# CM0+ register map
CPU: CM0+ r0p0, selectable endian, MPU, no FPU, 2 interrupt priority bits
Registers are 32-bit, read-write, reset 0x0 unless marked. A register's access mark holds for its fields unless they carry their own. Offsets are from the block's base; [hi:lo] are bit positions.

## SCB — System Control Block
Base 0xE000ED00
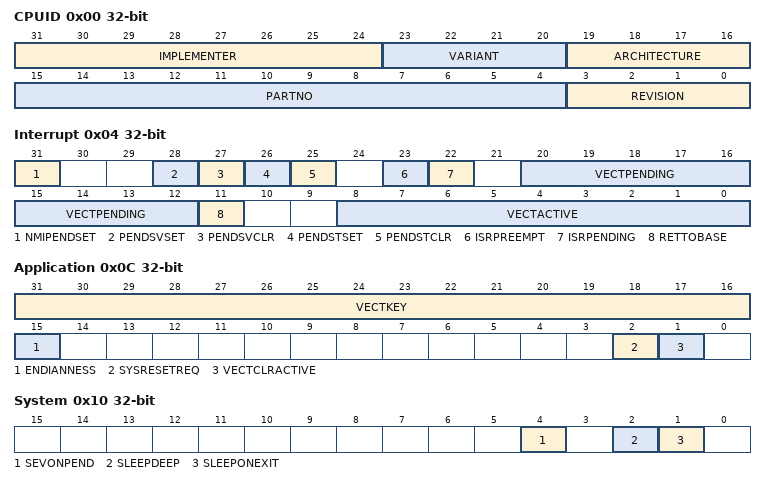
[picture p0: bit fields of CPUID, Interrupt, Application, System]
0x00 CPUID Base Register ro — Provides identification information for the processor
  [31:24] IMPLEMENTER — Implementer code assigned by ARM
  [23:20] VARIANT — IMPLEMENTATION DEFINED variant number
  [19:16] ARCHITECTURE — Reads as 0xF
  [15:4] PARTNO — IMPLEMENTATION DEFINED part number
  [3:0] REVISION — IMPLEMENTATION DEFINED revision number
0x04 Interrupt Control and State Register — Provides software control of the NMI, PendSV, and SysTick exceptions, and provides interrupt status information
  [31] NMIPENDSET write-1-sets — On writes, makes the NMI exception active
    0=cleared (On writes, has no effect. On reads, NMI is inactive); 1=set_pending (On writes, make the NMI exception active. On reads, NMI is active)
  [28] PENDSVSET write-1-sets — On writes, sets the PendSV exception as pending
    0=cleared (On writes, has no effect. On reads, PendSV is not pending); 1=set_pending (On writes, make PendSV exception pending. On reads, PendSV is pending)
  [27] PENDSVCLR write-1-sets — Removes the pending status of the PendSV exception
    0=No effect; 1=clear (Remove pending status)
  [26] PENDSTSET write-1-sets — On writes, sets the SysTick exception as pending
    0=cleared (On writes, has no effect. On reads, SysTick is not pending); 1=set_pending (On writes, make SysTick exception pending. On reads, SysTick is pending)
  [25] PENDSTCLR write-1-sets — Removes the pending status of the SysTick exception
    0=No effect; 1=clear (Remove pending status)
  [23] ISRPREEMPT — Indicates whether a pending exception will be serviced on exit from debug halt state
    0=Will not service; 1=Will service a pending exception
  [22] ISRPENDING — Indicates whether an external interrupt, generated by the NVIC, is pending
    0=No external interrupt pending; 1=External interrupt pending
  [20:12] VECTPENDING — The exception number of the highest priority pending and enabled interrupt
  [11] RETTOBASE — In Handler mode, indicates whether there is an active exception other than the exception indicated by the current value of the IPSR
    0=There is an active exception other than the exception shown by IPSR; 1=There is no active exception other than any exception shown by IPSR
  [8:0] VECTACTIVE — The exception number of the current executing exception
0x08 Vector Table Offset Register — Holds the vector table address
  [31:7] TBLOFF — Bits[31:7] of the vector table address
0x0C Application Interrupt and Reset Control Register — Sets or returns interrupt control data
  [31:16] VECTKEY range 0x05FA..0x05FA — Vector Key. The value 0x05FA must be written to this register.
    0=Do not request a reset; 0x5FA=Request reset
  [15] ENDIANNESS — Indicates the memory system endianness
    0=Little endian; 1=Big endian
  [2] SYSRESETREQ — System Reset Request
    0=Do not request a reset; 1=Request reset
  [1] VECTCLRACTIVE — Writing 1 to this bit clears all active state information for fixed and configurable exceptions
0x10 System Control Register — Sets or returns system control data
  [4] SEVONPEND — Determines whether an interrupt transition from inactive state to pending state is a wakeup event
    0=Transitions from inactive to pending are not wakeup events; 1=Transitions from inactive to pending are wakeup events
  [2] SLEEPDEEP — Provides a qualifying hint indicating that waking from sleep might take longer
    0=Selected sleep state is not deep sleep; 1=Selected sleep state is deep sleep
  [1] SLEEPONEXIT — Determines whether, on an exit from an ISR that returns to the base level of execution priority, the processor enters a sleep state
    0=Do not enter sleep state; 1=Enter sleep state
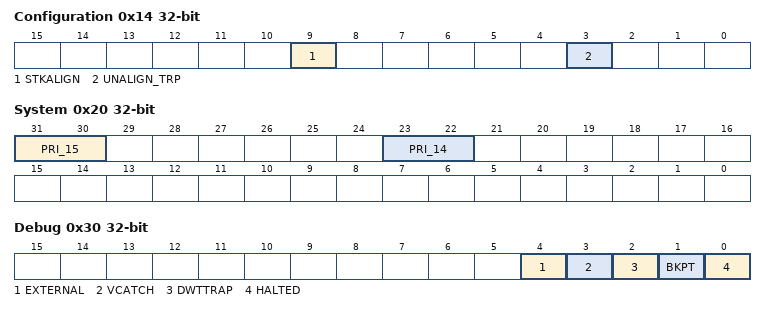
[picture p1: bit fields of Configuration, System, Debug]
0x14 Configuration and Control Register — Sets or returns configuration and control data, and provides control over caching and branch prediction
  [9] STKALIGN — Determines whether the exception entry sequence guarantees 8-byte stack frame alignment, adjusting the SP if necessary before saving state
    0=Guaranteed SP alignment is 4-byte, no SP adjustment is performed; 1=8-byte alignment guaranteed, SP adjusted if necessary
  [3] UNALIGN_TRP — Controls the trapping of unaligned word or halfword accesses
    0=Trapping disabled; 1=Trapping enabled
0x1C System Handler Priority Register 2 — Sets or returns priority for system handlers 8-11
  [31:30] PRI_11 — Priority of system handler 11, SVCall
0x20 System Handler Priority Register 3 — Sets or returns priority for system handlers 12-15
  [31:30] PRI_15 — Priority of system handler 15, SysTick
  [23:22] PRI_14 — Priority of system handler 14, PendSV
0x24 System Handler Control and State Register — Controls and provides the active and pending status of system exceptions
  [15] SVCALLPENDED
    0=SVCall is not pending; 1=SVCall is pending
0x30 Debug Fault Status Register — Shows which debug event occurred
  [4] EXTERNAL — Indicates a debug event generated because of the assertion of an external debug request
    0=No external debug request debug event; 1=External debug request debug event
  [3] VCATCH — Indicates triggering of a Vector catch
    0=No Vector catch triggered; 1=Vector catch triggered
  [2] DWTTRAP — Indicates a debug event generated by the DWT
    0=No debug events generated by the DWT; 1=At least one debug event generated by the DWT
  [1] BKPT — Indicates a debug event generated by BKPT instruction execution or a breakpoint match in FPB
    0=No breakpoint debug event; 1=At least one breakpoint debug event
  [0] HALTED — Indicates a debug event generated by either a halt or step request
    0=No halt request debug event; 1=Halt request debug event
